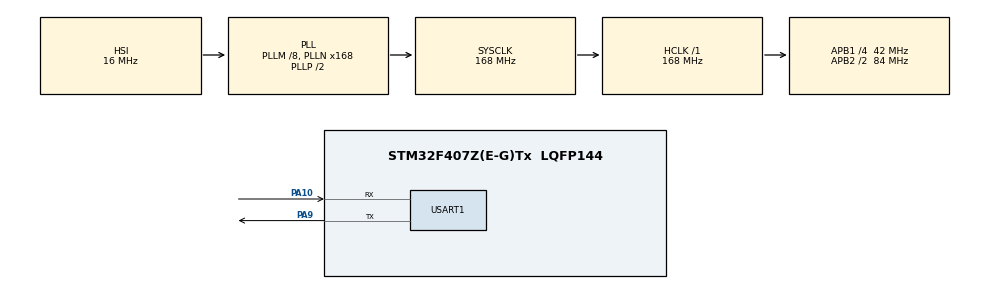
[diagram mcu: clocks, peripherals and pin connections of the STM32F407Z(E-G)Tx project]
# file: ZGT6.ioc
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Mcu.Family=STM32F4
Mcu.Name=STM32F407Z(E-G)Tx
Mcu.Package=LQFP144
NVIC.PriorityGroup=NVIC_PRIORITYGROUP_4
NVIC.USART1_IRQn=true\:0\:0\:false\:false\:true\:true\:true\:true
PA10.Mode=Asynchronous
PA10.Signal=USART1_RX
PA13.Mode=Serial_Wire
PA13.Signal=SYS_JTMS-SWDIO
PA14.Mode=Serial_Wire
PA14.Signal=SYS_JTCK-SWCLK
PA9.Mode=Asynchronous
PA9.Signal=USART1_TX
ProjectManager.HeapSize=0x800
ProjectManager.StackSize=0x800
ProjectManager.TargetToolchain=MDK-ARM V5.32
RCC.48MHZClocksFreq_Value=84000000
RCC.AHBFreq_Value=168000000
RCC.APB1CLKDivider=RCC_HCLK_DIV4
RCC.APB1Freq_Value=42000000
RCC.APB1TimFreq_Value=84000000
RCC.APB2CLKDivider=RCC_HCLK_DIV2
RCC.APB2Freq_Value=84000000
RCC.APB2TimFreq_Value=168000000
RCC.CortexFreq_Value=168000000
RCC.HCLKFreq_Value=168000000
RCC.HSE_VALUE=8000000
RCC.HSI_VALUE=16000000
RCC.LSE_VALUE=32768
RCC.PLLM=8
RCC.PLLN=168
RCC.SYSCLKFreq_VALUE=168000000
RCC.SYSCLKSource=RCC_SYSCLKSOURCE_PLLCLK
RCC.VCOOutputFreq_Value=336000000
STMicroelectronics.X-CUBE-AI.10.2.0.ActivationBufferSizeList=24376
STMicroelectronics.X-CUBE-AI.10.2.0.ActivationBuffers=pool0
STMicroelectronics.X-CUBE-AI.10.2.0.ActivationNames=pool0
STMicroelectronics.X-CUBE-AI.10.2.0.ActivationSizes=AI_NETWORK_DATA_ACTIVATION_1_SIZE
STMicroelectronics.X-CUBE-AI.10.2.0.ApplicationCcDeviceJjApplication=ApplicationTemplate
STMicroelectronics.X-CUBE-AI.10.2.0.HeapSize=0x800
STMicroelectronics.X-CUBE-AI.10.2.0.InternalRamActivationBufferMaxSize=AI_NETWORK_DATA_ACTIVATIONS_SIZE
STMicroelectronics.X-CUBE-AI.10.2.0.LatestDirectoryUsed-cc9ed3e1fa46f8964f744109dd600c300282d1206ee6c14dcb291ce6a92739e9=E\:\\STM32\\New Folder
STMicroelectronics.X-CUBE-AI.10.2.0.MaximumNumberOfInputLayer=1
STMicroelectronics.X-CUBE-AI.10.2.0.MaximumNumberOfOutputLayer=1
STMicroelectronics.X-CUBE-AI.10.2.0.MaximumSizeOfInputLayer=1
STMicroelectronics.X-CUBE-AI.10.2.0.MaximumSizeOfOutputLayer=1
STMicroelectronics.X-CUBE-AI.10.2.0.ModelActualCompression-cc9ed3e1fa46f8964f744109dd600c300282d1206ee6c14dcb291ce6a92739e9=0.0
STMicroelectronics.X-CUBE-AI.10.2.0.ModelCompression-cc9ed3e1fa46f8964f744109dd600c300282d1206ee6c14dcb291ce6a92739e9=None
STMicroelectronics.X-CUBE-AI.10.2.0.ModelFlashOccupation-cc9ed3e1fa46f8964f744109dd600c300282d1206ee6c14dcb291ce6a92739e9=0
STMicroelectronics.X-CUBE-AI.10.2.0.ModelHashList=cc9ed3e1fa46f8964f744109dd600c300282d1206ee6c14dcb291ce6a92739e9
STMicroelectronics.X-CUBE-AI.10.2.0.ModelKind-cc9ed3e1fa46f8964f744109dd600c300282d1206ee6c14dcb291ce6a92739e9=ONNX
STMicroelectronics.X-CUBE-AI.10.2.0.ModelMacc-cc9ed3e1fa46f8964f744109dd600c300282d1206ee6c14dcb291ce6a92739e9=418195
STMicroelectronics.X-CUBE-AI.10.2.0.ModelName-cc9ed3e1fa46f8964f744109dd600c300282d1206ee6c14dcb291ce6a92739e9=network
STMicroelectronics.X-CUBE-AI.10.2.0.ModelNameList=network
STMicroelectronics.X-CUBE-AI.10.2.0.ModelRamOccupation-cc9ed3e1fa46f8964f744109dd600c300282d1206ee6c14dcb291ce6a92739e9=0
STMicroelectronics.X-CUBE-AI.10.2.0.ModelType-cc9ed3e1fa46f8964f744109dd600c300282d1206ee6c14dcb291ce6a92739e9=STM32Cube.AI MCU runtime
STMicroelectronics.X-CUBE-AI.10.2.0.ReadyForCodeGeneration=true
STMicroelectronics.X-CUBE-AI.10.2.0.StackSize=0x800
STMicroelectronics.X-CUBE-AI.10.2.0.WorkingBufferStartAddrList=0xFFFFFFFF
STMicroelectronics.X-CUBE-AI.10.2.0.XAaCUBEAaAICcArtificialOoIntelligenceJjCore=true
STMicroelectronics.X-CUBE-AI.10.2.0.copyWeightToRam=false
STMicroelectronics.X-CUBE-AI.10.2.0.copyWeightToRam-cc9ed3e1fa46f8964f744109dd600c300282d1206ee6c14dcb291ce6a92739e9=false
STMicroelectronics.X-CUBE-AI.10.2.0.customLayerConfigEnabled=false
STMicroelectronics.X-CUBE-AI.10.2.0.customLayerConfigEnabled-cc9ed3e1fa46f8964f744109dd600c300282d1206ee6c14dcb291ce6a92739e9=false
STMicroelectronics.X-CUBE-AI.10.2.0.noOnnxIoTranspose=false
STMicroelectronics.X-CUBE-AI.10.2.0.noOnnxIoTranspose-cc9ed3e1fa46f8964f744109dd600c300282d1206ee6c14dcb291ce6a92739e9=false
STMicroelectronics.X-CUBE-AI.10.2.0.useInputAllocation=true
STMicroelectronics.X-CUBE-AI.10.2.0.useInputAllocation-cc9ed3e1fa46f8964f744109dd600c300282d1206ee6c14dcb291ce6a92739e9=true
STMicroelectronics.X-CUBE-AI.10.2.0.useOutputAllocation=true
STMicroelectronics.X-CUBE-AI.10.2.0.useOutputAllocation-cc9ed3e1fa46f8964f744109dd600c300282d1206ee6c14dcb291ce6a92739e9=true
USART1.VirtualMode=VM_ASYNC
VP_STMicroelectronics.X-CUBE-AI_VS_ArtificialOoIntelligenceJjXAaCUBEAaAI_10.2.0.Mode=ArtificialOoIntelligenceJjXAaCUBEAaAI
VP_STMicroelectronics.X-CUBE-AI_VS_DeviceJjApplication_10.2.0.Mode=DeviceJjApplication
board=custom

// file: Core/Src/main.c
/* USER CODE BEGIN Header */
/**
  ******************************************************************************
  * @file           : main.c
  * @brief          : Main program body
  ******************************************************************************
  * @attention
  *
  * Copyright (c) 2026 STMicroelectronics.
  * All rights reserved.
  *
  * This software is licensed under terms that can be found in the LICENSE file
  * in the root directory of this software component.
  * If no LICENSE file comes with this software, it is provided AS-IS.
  *
  ******************************************************************************
  */
/* USER CODE END Header */
#include "main.h"
#include "usart.h"
#include "gpio.h"
#include "app_x-cube-ai.h"

/* USER CODE BEGIN Includes */

#include <string.h>
#include <stdio.h>
#include <math.h>
#include "network.h"
/* USER CODE END Includes */

/* USER CODE BEGIN PV */

/* 串口通信全局变量定义 */
uint16_t uart_rx_length = 0;        // 已接收数据长度计数
uint8_t uart_rx_byte = 0;           // 单次接收字节缓存
uint8_t uart_rx_buffer[UART_BUFF_LEN];  // 接收缓冲区（存储上位机发送的完整数据）
volatile uint8_t goRunning = 0;     // 接收完成标志（0：未完成，1：已完成一帧接收）

/* AI模型输入输出缓冲区 */
float aiInData[28*28];              // AI模型输入数据（28*28=784个float值）
float aiOutData[10];                 // AI模型输出数据（0-9概率）

/* AI模型相关变量 */
extern ai_handle network;            // 从app_x-cube-ai.c导入网络句柄

/* USER CODE END PV */

void SystemClock_Config(void);

/* USER CODE BEGIN 0 */

/* 8位字节数组→32位浮点数数组（适配模型输入） */
void PictureCharArrayToFloat(uint8_t *srcBuf, float *dstBuf, int len)
{
  for (int i = 0; i < len; i++)
  {
    dstBuf[i] = srcBuf[i];  // 直接转换（若上位机数据有缩放，需在此处调整）
    // 可选：如需归一化处理，可改为 dstBuf[i] = srcBuf[i] / 255.0f;
  }
}

/* 串口发送字符串函数 */
void Uart_send(char * str)
{
  if (str != NULL) {
    uint16_t len = strlen(str);
    HAL_StatusTypeDef status = HAL_UART_Transmit(&huart1, (uint8_t *)str, len, 0xffff);
    if (status != HAL_OK) {
      // 发送失败时的处理
      char errMsg[50];
      sprintf(errMsg, "UART send failed: %d\r\n", status);
      // 尝试再次发送错误信息
      HAL_UART_Transmit(&huart1, (uint8_t *)errMsg, strlen(errMsg), 0xffff);
    }
  }
}

/* USER CODE END 0 */

int main(void)
{

  /* USER CODE BEGIN 1 */

  /* 系统启动开始 */
  /* USER CODE END 1 */

  /* MCU Configuration--------------------------------------------------------*/

  /* Reset of all peripherals, Initializes the Flash interface and the Systick. */
  HAL_Init();

  /* Configure the system clock */
  SystemClock_Config();

  /* Initialize all configured peripherals */
  MX_GPIO_Init();
  MX_USART1_UART_Init();
  /* 启动串口接收中断 */
  HAL_UART_Receive_IT(&huart1, (uint8_t *)&uart_rx_byte, 1);
  printf("USART1 initialized\r\n");
  MX_X_CUBE_AI_Init();
  /* USER CODE BEGIN 2 */

  printf("System startup completed\r\n");
  printf("Ready to receive data\r\n");

  /* USER CODE END 2 */

  /* Infinite loop */
  while (1)
  {

  MX_X_CUBE_AI_Process();
    /* USER CODE BEGIN 3 */
    if (goRunning > 0)  // 检测到一帧数据接收完成
    {
      if (uart_rx_length == ONE_FRAME_LEN)  // 验证数据长度是否正确
      {
        // 检查AI网络是否初始化成功
        if (network != AI_HANDLE_NULL) {
          // 数据格式转换：上位机8位数据→单片机32位浮点数（适配模型输入）
          PictureCharArrayToFloat(uart_rx_buffer + 1, aiInData, 28*28);

          // 准备AI模型输入数据
          ai_buffer* input = ai_network_inputs_get(network, NULL);
          if (input) {
            // 将aiInData复制到模型输入缓冲区
            memcpy(input[0].data, aiInData, sizeof(aiInData));

            // 准备AI模型输出缓冲区
            ai_buffer* output = ai_network_outputs_get(network, NULL);
            if (output) {
              // AI推理：输入手写数据，输出识别结果
              ai_i32 batch = ai_network_run(network, input, output);
              if (batch == 1) {
                // 从模型输出获取识别结果
                memcpy(aiOutData, output[0].data, sizeof(aiOutData));

                // 计算指数值和百分比
                int count = 0;
                float max = aiOutData[0];
                float exp_values[10];
                float exp_sum = 0;
                char logStr[100];

                // 发送自然常数e的值
                Uart_send("Natural constant e ~= 2.71828\r\n\r\n");

                // 发送表头
                Uart_send("Num  Score      Exp       Prob(%)\r\n");

                // 计算指数值和指数和
                for (uint32_t i = 0; i < 10; i++) {
                  exp_values[i] = exp(aiOutData[i]);
                  exp_sum += exp_values[i];
                }

                // 发送每个数字的详细信息
                for (uint32_t i = 0; i < 10; i++) {
                  float probability = (exp_values[i] / exp_sum) * 100;
                  sprintf(logStr, "%d    %8.6f   %.3f     %.2f\r\n", i, aiOutData[i], exp_values[i], probability);
                  Uart_send(logStr);
                  // 查找概率最大值对应的数字
                  if (max < aiOutData[i]) {
                    count = i;
                    max = aiOutData[i];
                  }
                }

                // 发送分隔线
                Uart_send("-----------------\r\n");

                // 发送指数和
                sprintf(logStr, "Exponential sum: %.3f\r\n", exp_sum);
                Uart_send(logStr);

                // 发送分隔线
                Uart_send("-----------------\r\n");

                // 计算最终结果的百分比
                float final_probability = (exp(max) / exp_sum) * 100;

                // 发送最终识别结果
                sprintf(logStr, "current number is %d\r\n", count);
                Uart_send(logStr);

                // 发送概率值
                sprintf(logStr, "probability: %8.6f (%.2f%%)\r\n", max, final_probability);
                Uart_send(logStr);
              } else {
                Uart_send("AI inference failed\r\n");
              }
            } else {
              Uart_send("Failed to get AI network outputs\r\n");
            }
          } else {
            Uart_send("Failed to get AI network inputs\r\n");
          }
        } else {
          Uart_send("AI network not initialized\r\n");
        }
      } else {
        char errorMsg[100];
        sprintf(errorMsg, "Invalid data length: %d (expected: %d)\r\n", uart_rx_length, ONE_FRAME_LEN);
        Uart_send(errorMsg);
      }
      // 重置接收状态，准备下一帧接收
      memset(uart_rx_buffer, 0, UART_BUFF_LEN);  // 清空缓冲区
      goRunning = 0;                   // 重置接收完成标志
      uart_rx_length = 0;              // 重置接收长度计数
    }
  }
  /* USER CODE END 3 */
}

void SystemClock_Config(void)
{
  RCC_OscInitTypeDef RCC_OscInitStruct = {0};
  RCC_ClkInitTypeDef RCC_ClkInitStruct = {0};

  /** Configure the main internal regulator output voltage
  */
  __HAL_RCC_PWR_CLK_ENABLE();
  __HAL_PWR_VOLTAGESCALING_CONFIG(PWR_REGULATOR_VOLTAGE_SCALE1);

  /** Initializes the RCC Oscillators according to the specified parameters
  * in the RCC_OscInitTypeDef structure.
  */
  RCC_OscInitStruct.OscillatorType = RCC_OSCILLATORTYPE_HSI;
  RCC_OscInitStruct.HSIState = RCC_HSI_ON;
  RCC_OscInitStruct.HSICalibrationValue = RCC_HSICALIBRATION_DEFAULT;
  RCC_OscInitStruct.PLL.PLLState = RCC_PLL_ON;
  RCC_OscInitStruct.PLL.PLLSource = RCC_PLLSOURCE_HSI;
  RCC_OscInitStruct.PLL.PLLM = 8;
  RCC_OscInitStruct.PLL.PLLN = 168;
  RCC_OscInitStruct.PLL.PLLP = RCC_PLLP_DIV2;
  RCC_OscInitStruct.PLL.PLLQ = 4;
  if (HAL_RCC_OscConfig(&RCC_OscInitStruct) != HAL_OK)
  {
    Error_Handler();
  }

  /** Initializes the CPU, AHB and APB buses clocks
  */
  RCC_ClkInitStruct.ClockType = RCC_CLOCKTYPE_HCLK|RCC_CLOCKTYPE_SYSCLK
                              |RCC_CLOCKTYPE_PCLK1|RCC_CLOCKTYPE_PCLK2;
  RCC_ClkInitStruct.SYSCLKSource = RCC_SYSCLKSOURCE_PLLCLK;
  RCC_ClkInitStruct.AHBCLKDivider = RCC_SYSCLK_DIV1;
  RCC_ClkInitStruct.APB1CLKDivider = RCC_HCLK_DIV4;
  RCC_ClkInitStruct.APB2CLKDivider = RCC_HCLK_DIV2;

  if (HAL_RCC_ClockConfig(&RCC_ClkInitStruct, FLASH_LATENCY_5) != HAL_OK)
  {
    Error_Handler();
  }
}

/* USER CODE BEGIN 4 */

/* 串口接收中断回调函数 */
void HAL_UART_RxCpltCallback(UART_HandleTypeDef *UartHandle)
{
  if(goRunning == 0)  // 未开始接收或上一帧已处理完成
  {
    if (uart_rx_length < UART_BUFF_LEN)  // 缓冲区未溢出
    {
      uart_rx_buffer[uart_rx_length] = uart_rx_byte;  // 存储接收字节
      uart_rx_length++;

      if (uart_rx_byte == '\n')  // 检测到帧尾（换行符），接收完成
      {
        goRunning = 1;  // 置位接收完成标志，通知主循环处理数据
      }
    }
    else
    {
      // 缓冲区溢出，重置计数
      uart_rx_length = 0;
    }
  }
  // 重新开启中断接收（单次中断仅接收1字节，需循环开启）
  HAL_UART_Receive_IT(&huart1, (uint8_t *)&uart_rx_byte, 1);
}

/* USER CODE END 4 */

void Error_Handler(void)
{
  /* USER CODE BEGIN Error_Handler_Debug */
  /* User can add his own implementation to report the HAL error return state */
  __disable_irq();
  //while (1)
  //{
  //}
  /* USER CODE END Error_Handler_Debug */
}

/* USER CODE BEGIN 6 */

/* 重定向 fputc 函数到 USART1，使 printf 函数可以通过串口输出 */
int fputc(int ch, FILE *f)
{
  HAL_UART_Transmit(&huart1, (uint8_t *)&ch, 1, 0xffff);
  return ch;
}

/* USER CODE END 6 */
